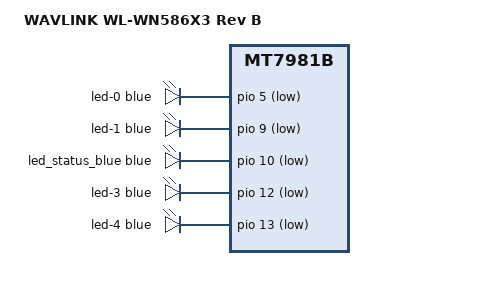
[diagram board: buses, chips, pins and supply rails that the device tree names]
// SPDX-License-Identifier: (GPL-2.0 OR MIT)

/dts-v1/;

#include "mt7981b-wavlink-wl-3port-128nand-common.dtsi"

/ {
	model = "WAVLINK WL-WN586X3 Rev B";
	compatible = "wavlink,wl-wn586x3b", "mediatek,mt7981b";

	aliases {
		label-mac-device = &wifi;
		led-boot = &led_status_blue;
		led-failsafe = &led_status_blue;
		led-running = &led_status_blue;
		led-upgrade = &led_status_blue;
		serial0 = &uart0;
	};

	leds {
		compatible = "gpio-leds";

		led-0 {
			color = <LED_COLOR_ID_BLUE>;
			function = LED_FUNCTION_WAN;
			gpios = <&pio 5 GPIO_ACTIVE_LOW>;
		};

		led-1 {
			color = <LED_COLOR_ID_BLUE>;
			function = LED_FUNCTION_WLAN;
			gpios = <&pio 9 GPIO_ACTIVE_LOW>;
			linux,default-trigger = "phy1tpt";
		};

		led_status_blue: led-2 {
			color = <LED_COLOR_ID_BLUE>;
			function = LED_FUNCTION_STATUS;
			gpios = <&pio 10 GPIO_ACTIVE_LOW>;
		};

		led-3 {
			color = <LED_COLOR_ID_BLUE>;
			function = LED_FUNCTION_LAN;
			function-enumerator = <1>;
			gpios = <&pio 12 GPIO_ACTIVE_LOW>;
		};

		led-4 {
			color = <LED_COLOR_ID_BLUE>;
			function = LED_FUNCTION_LAN;
			function-enumerator = <2>;
			gpios = <&pio 13 GPIO_ACTIVE_LOW>;
		};

	};
};
